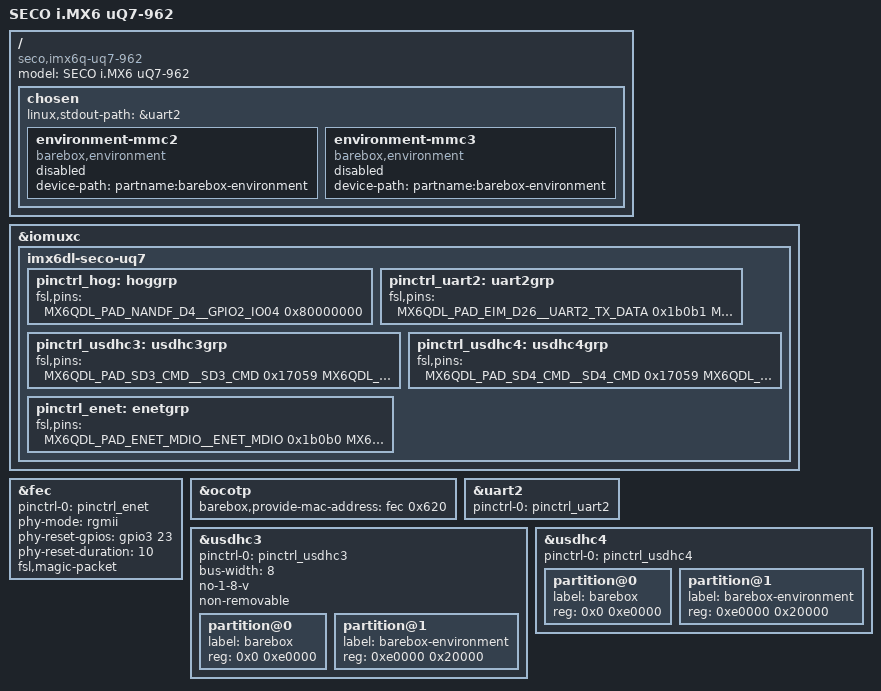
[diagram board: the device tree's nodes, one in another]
/*
 * Copyright 2011 Freescale Semiconductor, Inc.
 * Copyright 2011 Linaro Ltd.
 *
 * The code contained herein is licensed under the GNU General Public
 * License. You may obtain a copy of the GNU General Public License
 * Version 2 or later at the following locations:
 *
 * http://www.opensource.org/licenses/gpl-license.html
 * http://www.gnu.org/copyleft/gpl.html
 */

/dts-v1/;
#include <dt-bindings/gpio/gpio.h>
#include <dt-bindings/input/input.h>
#include <arm/imx6q.dtsi>
#include "imx6q.dtsi"

/ {
	model = "SECO i.MX6 uQ7-962";
	compatible = "seco,imx6q-uq7-962", "fsl,imx6q";

	chosen {
		linux,stdout-path = &uart2;

		/* When booting from eMMC */
		environment-mmc2 {
			compatible = "barebox,environment";
			device-path = &usdhc3, "partname:barebox-environment";
			status = "disabled";
		};

		/* When booting from SD card */
		environment-mmc3 {
			compatible = "barebox,environment";
			device-path = &usdhc4, "partname:barebox-environment";
			status = "disabled";
		};
	};
};

&iomuxc {
	pinctrl-names = "default";

	imx6dl-seco-uq7 {
		pinctrl_hog: hoggrp {
			fsl,pins = <
				/* BOOT validate */
				MX6QDL_PAD_NANDF_D4__GPIO2_IO04		0x80000000
			>;
		};

		pinctrl_uart2: uart2grp {
			fsl,pins = <
				MX6QDL_PAD_EIM_D26__UART2_TX_DATA	0x1b0b1
				MX6QDL_PAD_EIM_D27__UART2_RX_DATA	0x1b0b1
			>;
		};

		pinctrl_usdhc3: usdhc3grp {
			fsl,pins = <
				MX6QDL_PAD_SD3_CMD__SD3_CMD		0x17059
				MX6QDL_PAD_SD3_CLK__SD3_CLK		0x10059
				MX6QDL_PAD_SD3_DAT0__SD3_DATA0		0x17059
				MX6QDL_PAD_SD3_DAT1__SD3_DATA1		0x17059
				MX6QDL_PAD_SD3_DAT2__SD3_DATA2		0x17059
				MX6QDL_PAD_SD3_DAT3__SD3_DATA3		0x17059
				MX6QDL_PAD_SD3_DAT4__SD3_DATA4		0x17059
				MX6QDL_PAD_SD3_DAT5__SD3_DATA5		0x17059
				MX6QDL_PAD_SD3_DAT6__SD3_DATA6		0x17059
				MX6QDL_PAD_SD3_DAT7__SD3_DATA7		0x17059
				MX6QDL_PAD_SD3_RST__SD3_RESET		0x17059
			>;
		};

		pinctrl_usdhc4: usdhc4grp {
			fsl,pins = <
				MX6QDL_PAD_SD4_CMD__SD4_CMD		0x17059
				MX6QDL_PAD_SD4_CLK__SD4_CLK		0x10059
				MX6QDL_PAD_SD4_DAT0__SD4_DATA0		0x17059
				MX6QDL_PAD_SD4_DAT1__SD4_DATA1		0x17059
				MX6QDL_PAD_SD4_DAT2__SD4_DATA2		0x17059
				MX6QDL_PAD_SD4_DAT3__SD4_DATA3		0x17059
				MX6QDL_PAD_SD4_DAT4__SD4_DATA4		0x17059
				MX6QDL_PAD_SD4_DAT5__SD4_DATA5		0x17059
				MX6QDL_PAD_SD4_DAT6__SD4_DATA6		0x17059
				MX6QDL_PAD_SD4_DAT7__SD4_DATA7		0x17059
			>;
		};

		pinctrl_enet: enetgrp {
			fsl,pins = <
				MX6QDL_PAD_ENET_MDIO__ENET_MDIO              0x1b0b0
				MX6QDL_PAD_ENET_MDC__ENET_MDC                0x1b0b0
				MX6QDL_PAD_RGMII_RD0__RGMII_RD0              0x1b0b0
				MX6QDL_PAD_RGMII_RD1__RGMII_RD1              0x1b0b0
				MX6QDL_PAD_RGMII_RD2__RGMII_RD2              0x1b0b0
				MX6QDL_PAD_RGMII_RD3__RGMII_RD3              0x1b0b0
				MX6QDL_PAD_RGMII_RX_CTL__RGMII_RX_CTL        0x1b0b0
				MX6QDL_PAD_RGMII_TD0__RGMII_TD0              0x1b0b0
				MX6QDL_PAD_RGMII_TD1__RGMII_TD1              0x1b0b0
				MX6QDL_PAD_RGMII_TD2__RGMII_TD2              0x1b0b0
				MX6QDL_PAD_RGMII_TD3__RGMII_TD3              0x1b0b0
				MX6QDL_PAD_RGMII_TX_CTL__RGMII_TX_CTL        0x1b0b0
				MX6QDL_PAD_RGMII_RXC__RGMII_RXC              0x1b0b0
				MX6QDL_PAD_RGMII_TXC__RGMII_TXC              0x1b0b0
				MX6QDL_PAD_ENET_REF_CLK__ENET_TX_CLK         0x1b0b0

				/* ENET RESET */
				MX6QDL_PAD_EIM_D23__GPIO3_IO23               0x1f071
				/* ENET CLK125_EN */
				MX6QDL_PAD_RGMII_RX_CTL__GPIO6_IO24             0x1f071
			>;
		};
	};
};

&fec {
	pinctrl-names = "default";
	pinctrl-0 = <&pinctrl_enet>;
	phy-mode = "rgmii";
	phy-reset-gpios = <&gpio3 23 0>;
	phy-reset-duration = <10>;
	fsl,magic-packet;
	status = "okay";
};

&ocotp {
	barebox,provide-mac-address = <&fec 0x620>;
};

&uart2 {
	pinctrl-names = "default";
	pinctrl-0 = <&pinctrl_uart2>;
	status = "okay";
};

&usdhc3 {
	pinctrl-names = "default";
	pinctrl-0 = <&pinctrl_usdhc3>;
	bus-width = <8>;
	no-1-8-v;
	non-removable;
	status = "okay";

	#address-cells = <1>;
	#size-cells = <1>;

	partition@0 {
		label = "barebox";
		reg = <0x0 0xe0000>;
	};
	partition@1 {
		label = "barebox-environment";
		reg = <0xe0000 0x20000>;
	};
};

&usdhc4 {
	pinctrl-names = "default";
	pinctrl-0 = <&pinctrl_usdhc4>;
	status = "okay";

	#address-cells = <1>;
	#size-cells = <1>;

	partition@0 {
		label = "barebox";
		reg = <0x0 0xe0000>;
	};
	partition@1 {
		label = "barebox-environment";
		reg = <0xe0000 0x20000>;
	};
};
